# VPFE register map
Vendor: Texas Instruments
Peripheral module from a debugger description file (folder am437x).
Registers are 32-bit, access per field, no defined reset value unless marked. A register's access mark holds for its fields unless they carry their own. Offsets are as the file gives them; lines under a group give offsets from that group; [hi:lo] are bit positions; {n}, {i} and the like mark numbered series; 'fields as' and 'values as' point back to an identical list; <NAME> marks a mode.

## VPFE
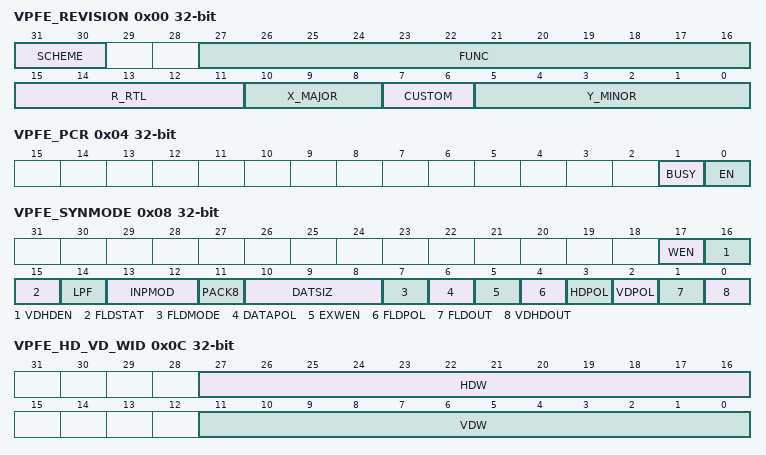
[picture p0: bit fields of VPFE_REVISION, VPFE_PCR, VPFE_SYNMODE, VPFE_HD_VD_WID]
0x00 VPFE_REVISION ro — IP Revision Identifier (X.Y.R) Used by software to track features, bugs, and compatibility
  [31:30] SCHEME — Used to distinguish between old scheme and current.
  [27:16] FUNC — Function value
  [15:11] R_RTL — RTL Version (R), maintained by IP design owner. [[br]]
  [10:8] X_MAJOR — Major Revision (X), maintained by IP specification owner. [[br]]
  [7:6] CUSTOM — Custom version
  [5:0] Y_MINOR — Minor Revision (Y), maintained by IP specification owner. [[br]]
0x04 VPFE_PCR — Peripheral Control Register
  [1] BUSY ro — VPFE busy bit
    1=en_2_0x1 (Busy); 0=en_1_0x0 (Not busy)
  [0] EN rw — This bit is latched by VD (start of frame)
    1=en_2_0x1 (Enable); 0=en_1_0x0 (Disable)
0x08 VPFE_SYNMODE — SYNC and Mode Set Register
  [17] WEN rw — Data write enable. [[br]]Controls whether or not input raw data is written to external memory. [[br]]This bit is latched by VD. [[br]]
    1=en_2_0x1 (Enable); 0=en_1_0x0 (Disable)
  [16] VDHDEN rw — VD/HD enable. [[br]]Activates internal timing generator to synchronize with external VD/HD signals. [[br]]This bit should be set to 1 when HD and VD signals are used at any time.
    1=en_2_0x1 (Enable); 0=en_1_0x0 (Disable)
  [15] FLDSTAT rw — Field status. [[br]]Indicates the status of the current field when in interlaced mode.
    1=en_2_0x1 (Even field); 0=en_1_0x0 (Odd field)
  [14] LPF rw — [[br]]3-tap low-pass (anti-aliasing) filter. [[br]]This bit is latched by VD.
    1=en_2_0x1 (On); 0=en_1_0x0 (Off)
  [13:12] INPMOD rw — Setting data input mode
    3=en_4_0x3 (Reserved); 2=en_3_0x2 (YCbCr 8-bit); 1=en_2_0x1 (YCbCr 16-bit); 0=en_1_0x0 (Raw data)
  [11] PACK8 rw — Pack to [[br]]8-bit/pixel (into external memory)
    1=en_2_0x1 (Pack to 8 bits/pixel); 0=en_1_0x0 (Normal (16 bits/pixel))
  [10:8] DATSIZ rw — CCD data width is only valid when INPMOD is set to 0.
    7=en_8_0x7 (8 bits); 6=en_7_0x6 (10 bits); 5=en_6_0x5 (11 bits); 4=en_5_0x4 (12 bits); 3=en_4_0x3 (13 bits); 2=en_3_0x2 (14 bits); 1=en_2_0x1 (15 bits); 0=en_1_0x0 (16 bits)
  [7] FLDMODE rw — Sensor field mode
    1=en_2_0x1 (Interlaced); 0=en_1_0x0 (Non-interlaced (progressive))
  [6] DATAPOL rw — Input data polarity
    1=en_2_0x1 (One's complement); 0=en_1_0x0 (Normal (no charge))
  [5] EXWEN rw — External WEN selection. [[br]]When set to 1 and when VDHDEN is set to 1, the WEN signal is used as the external memory write enable (to external memory). [[br]]The data is stored to memory only when the external sync (HD and VD) signals are active.
    1=en_2_0x1 (Use external WEN (write enable)); 0=en_1_0x0 (Do not use external WEN (write enable))
  [4] FLDPOL rw — Field indicator polarity
    1=en_2_0x1 (Negative); 0=en_1_0x0 (Positive)
  [3] HDPOL rw — HD sync polarity
    1=en_2_0x1 (Negative); 0=en_1_0x0 (Positive)
  [2] VDPOL rw — VD sync polarity
    1=en_2_0x1 (Negative); 0=en_1_0x0 (Positive)
  [1] FLDOUT rw — Field ID Direction
    1=en_2_0x1 (Output); 0=en_1_0x0 (Input)
  [0] VDHDOUT rw — VD/HD Sync Direction
    1=en_2_0x1 (Output); 0=en_1_0x0 (Input)
0x0C VPFE_HD_VD_WID
  [27:16] HDW rw — Width of HD sync pulse if output HDW+1 pixel clocks HDWIDTH is not used when HD is input, i.e when VDHDOUT in SYN_MODE register is cleared to '0' *This bit field is latched by VD
  [11:0] VDW rw — Width of VD sync pulse if output VDW+1 lines VDWIDTH is not used when VD is input, i.e when VDHDOUT in SYN_MODE register is cleared to '0' *This bit field is latched by VD
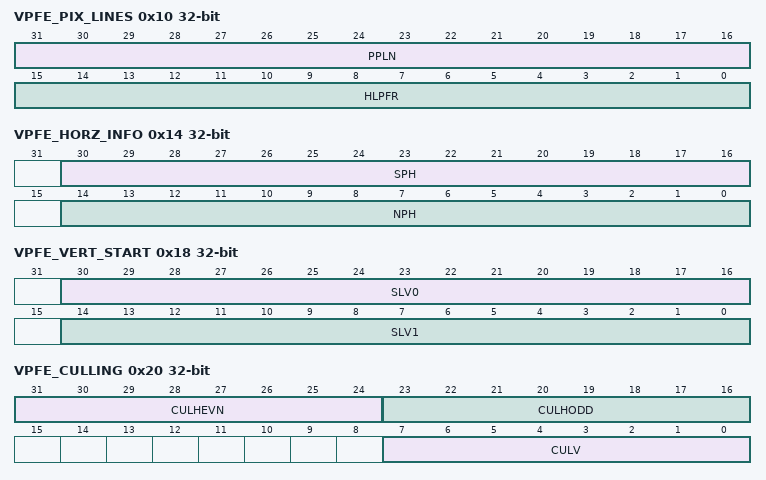
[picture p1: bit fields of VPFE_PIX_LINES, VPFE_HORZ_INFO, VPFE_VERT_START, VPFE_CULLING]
0x10 VPFE_PIX_LINES rw — Number of pixels in a horizontal line and number of lines in a frame
  [31:16] PPLN — Pixels per line - number of pixel clock periods in one line HD period = PPLN+1 pixel clocks PPLN is not used when HD and VD are inputs, i.e when VDHDOUT in SYN_MODE register is cleared to '0' *This bit field is latched by VD
  [15:0] HLPFR — Half lines per field or frame - sets number of half lines per frame or field VD period = (HLPFR+1)/2 lines HLPFR is not used when HD and VD are inputs, i.e when VDHDOUT in SYN_MODE register is cleared to '0' This tells the internal timing generator to generate the sufficient number of HD pulses in between two VD pulses. [[br]]If the sensor is an interlaced sensor, say for example, with a total of 525 (or 526) lines, then this field should be set to 525 (or 526). [[br]]This means that 525 (or 526) half lines are written for each field. [[br]]If the sensor is progressive, then this register should be set to be twice the number of lines to be written. [[br]]For example, if sensor outputs 1024 lines, this field should be set to 2048. [[br]]Therefore, for interlaced sensors, this field should be set to the total number of lines. [[br]]For progressive sensors, this field should be set to twice the total number of lines. [[br]]*This bit field is latched by VD
0x14 VPFE_HORZ_INFO — Horizontal Pixel Information Register
  [30:16] SPH rw — Start pixel, horizontal. [[br]]The SPH sets the pixel clock position at which data output to external memory begins, measured from the start of HD. [[br]]This bit field is latched by VD.
  [14:0] NPH rw — Number of pixels, horizontal. [[br]]NPH sets the number of horizontal pixels that is output to external memory = (NPH + 1) and 0xFFF0 (i.e., the number of horizontal output pixels truncates to multiples of 16). [[br]]This bit field is latched by VD.
0x18 VPFE_VERT_START — Vertical Line - Settings for the Starting Pixel Register
  [30:16] SLV0 rw — Start line, vertical (field 0). [[br]]SLV0 sets line at which data output to external memory will begin, measured from the start of VD. [[br]]This bit field is latched by VD.
  [14:0] SLV1 rw — Start line, vertical (field 1). [[br]]SLV1 sets line at which data output to external memory will begin, measured from the start of VD. [[br]]For a progressive sensor this field is ignored. [[br]]This bit field is latched by VD.
0x1C VPFE_VERT_LINES — Number of Vertical Lines Register
  [14:0] NLV rw — Number of lines, vertical. [[br]]NLV sets the number of vertical lines that will be output to external memory. [[br]]The number of lines output to external memory = (NLV + 1). [[br]]This bit field is latched by VD.
0x20 VPFE_CULLING — Culling Information in Horizontal and Vertical Directions Register
  [all] fields
    1=en_2_0x1 (Retain (to be saved to external memory)); 0=en_1_0x0 (CULLING (deletion))
  [31:24] CULHEVN rw — Horizontal Culling Pattern for Even Line, [[br]]8-bit mask. [[br]]LSB is first pixel, MSB is 8th pixel, then pattern repeats. [[br]]This bit field is latched by VD.
  [23:16] CULHODD rw — Horizontal Culling Pattern for Odd Line, [[br]]8-bit mask. [[br]]LSB is first pixel, MSB is 8th pixel, then pattern repeats. [[br]]This bit field is latched by VD.
  [7:0] CULV rw — Vertical Culling Pattern, [[br]]8-bit mask. [[br]]LSB is first line, MSB is 8th line, then pattern repeats. [[br]]This bit field is latched by VD.
0x24 VPFE_HSIZE_OFF — Horizontal Size Register
  [15:0] LNOFST rw — Address offset for each line. [[br]]LNOFST Sets offset for each output line in external memory Either 16 or 32 pixels depending on setting of PACK8. [[br]]The 5 LSB are ignored, and a zero is returned when read[[br]] the offset will be on a [[br]]32-byte boundary. [[br]]For optimal performance in the system, the address offset should be on a [[br]]256-byte boundary. [[br]]This bit field is latched by VD.
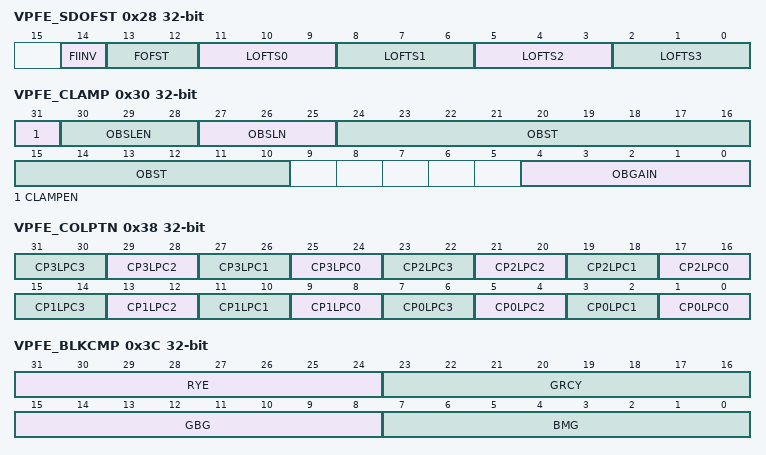
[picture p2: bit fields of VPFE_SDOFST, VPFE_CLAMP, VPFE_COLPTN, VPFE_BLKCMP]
0x28 VPFE_SDOFST — External Memory Line Offset Register
  [14] FIINV rw — Field identification signal inverse. [[br]]This field is latched by VD.
    1=en_2_0x1 (Inverse); 0=en_1_0x0 (Non inverse)
  [13:12] FOFST rw — Line offset value of field ID = 1. [[br]]This field is latched by VD.
    3=en_4_0x3 (+4 lines); 2=en_3_0x2 (+3 lines); 1=en_2_0x1 (+2 lines); 0=en_1_0x0 (+1 line)
  [11:9] LOFTS0 rw — Line offset values of even line and even field ID = 0. [[br]]This field is latched by VD.
    7=en_8_0x7 (-4 lines); 6=en_7_0x6 (-3 lines); 5=en_6_0x5 (-2 lines); 4=en_5_0x4 (-1 line); 3=en_4_0x3 (+4 lines); 2=en_3_0x2 (+3 lines); 1=en_2_0x1 (+2 lines); 0=en_1_0x0 (+1 line)
  [8:6] LOFTS1 rw — Line offset values of odd line and even field ID = 0. [[br]]This field is latched by VD.
    values as LOFTS0
  [5:3] LOFTS2 rw — Line offset values of even line and odd field ID = 1. [[br]]This field is latched by VD.
    values as LOFTS0
  [2:0] LOFTS3 rw — Line offset values of odd line and odd field ID = 1. [[br]]This field is latched by VD.
    values as LOFTS0
0x2C VPFE_SDR_ADDR rw — External Memory Address Register
  [31:0] ADR — 32-bit external memory starting address for VPFE output. [[br]]This bit field is latched by VD. [[br]]The address should be aligned on a 32-byte boundary. [[br]]Therefore, the 5 LSB's are ignored. [[br]]Furthermore, reading this register will always show the 5 LSB's as 0. [[br]]For optimal performance in the system, the address should be on a 256-byte boundary. [[br]]
0x30 VPFE_CLAMP — Optical Black Clamping Setting Register
  [31] CLAMPEN rw — Clamp enable. [[br]]Enable or disable clamping of CCD data based on the calculated average of optical black samples. [[br]]This bit is latched by VD.
    1=en_2_0x1 (Enable); 0=en_1_0x0 (Disable)
  [30:28] OBSLEN rw — Optical black sample length. [[br]]Number of Optical Black Sample pixels per line to include in the average calculation
    7=en_8_0x7 (Reserved); 6=en_7_0x6 (Reserved); 5=en_6_0x5 (Reserved); 4=en_5_0x4 (16 pixels); 3=en_4_0x3 (8 pixels); 2=en_3_0x2 (4 pixels); 1=en_2_0x1 (2 pixels); 0=en_1_0x0 (1 pixels)
  [27:25] OBSLN rw — Optical black sample lines. [[br]]Number of Optical Black Sample lines to include in the average calculation
    7=en_8_0x7 (Reserved); 6=en_7_0x6 (Reserved); 5=en_6_0x5 (Reserved); 4=en_5_0x4 (16 lines); 3=en_4_0x3 (8 lines); 2=en_3_0x2 (4 lines); 1=en_2_0x1 (2 lines); 0=en_1_0x0 (1 lines)
  [24:10] OBST rw — Start pixel of optical black samples. [[br]]The start pixel position of optical black samples, specified from the start of HD in pixel clocks.
  [4:0] OBGAIN rw — Gain to apply to the optical black average. [[br]]Multiply the optical black average with the specified gain. [[br]]1Fh = 1 + 15/16 1Eh = 1 + 14/16 ... [[br]]= ... [[br]]10h = 1 + 0/16 0Fh = 0 + 15/16 0Eh = 0 + 14/16 0Dh = 0 + 13/16 ... [[br]]= ... [[br]]02h = 0 + 2/16 01h = 0 + 1/16 00h = 0 + 0/16
0x34 VPFE_DCSUB — DC Clamp Register
  [13:0] DCSUB rw — DC level to subtract from CCD data. [[br]]The DC value set here is subtracted from the CCD data when OBS clamping is disabled - CLAMP.CLAMPEN.
0x38 VPFE_COLPTN rw — CCD Color Pattern Register
  [all] fields
    3=en_4_0x3 (B/Mg); 2=en_3_0x2 (Gb/G); 1=en_2_0x1 (Gr/Cy); 0=en_1_0x0 (R/Ye)
  [2n+25:2n+24] CP3LPC{n} (n=0..3) — Color Pattern for 3rd Line, Pixel counter = {n}
  [2n+17:2n+16] CP2LPC{n} (n=0..3) — Color Pattern for 2nd Line, Pixel counter = {n}
  [2n+9:2n+8] CP1LPC{n} (n=0..3) — Color Pattern for 1st Line, Pixel counter = {n}
  [2n+1:2n] CP0LPC{n} (n=0..3) — Color Pattern for 0th Line, Pixel counter = {n}
0x3C VPFE_BLKCMP rw — Black Compensation Register
  [31:24] RYE — Black level compensation for R/Ye pixels (-[[br]]128:+127). [[br]]2's complement, MSB is sign bit.
  [23:16] GRCY — Black level compensation for Gr/Cy pixels (-[[br]]128:+127). [[br]]2's complement, MSB is sign bit.
  [15:8] GBG — Black level compensation for Gb/G pixels (-[[br]]128:+127). [[br]]2's complement, MSB is sign bit.
  [7:0] BMG — Black level compensation for B/Mg pixels (-[[br]]128:+127). [[br]]2's complement, MSB is sign bit.
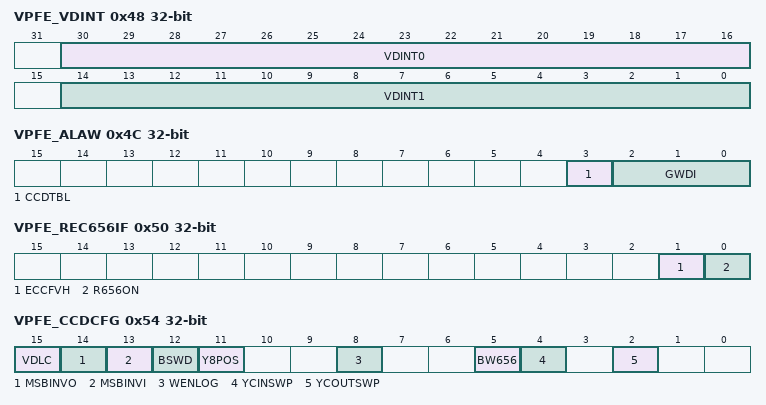
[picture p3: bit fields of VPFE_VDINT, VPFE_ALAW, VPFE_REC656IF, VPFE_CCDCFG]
0x48 VPFE_VDINT — VPFE Interrupt Control Register
  [30:16] VDINT0 rw — CCDC_VD0_INT interrupt timing. [[br]]Specify VDINT0 in units of horizontal lines from the start of VD pulse. [[br]]Resulting value is VDINT0+1. [[br]]Note that if the rising edge (or falling edge if programmed) of the HD lines up with the rising edge (or falling edge if programmed) of VD, the 1st HD is not counted. [[br]]
  [14:0] VDINT1 rw — CCDC_VD1_INT interrupt timing. [[br]]Specify VDINT1 in units of horizontal lines from the start of VD pulse. [[br]]Resulting value is VDINT1+1. [[br]]Note that if the rising edge (or falling edge if programmed) of the HD lines up with the rising edge (or falling edge if programmed) of VD, the 1st HD is not counted. [[br]]
0x4C VPFE_ALAW — ALAW Configuration Register
  [3] CCDTBL rw — Apply Gamma (A-LAW) to VPFE data saved to external memory
    1=en_2_0x1 (Enable); 0=en_1_0x0 (Disable)
  [2:0] GWDI rw — A-law Width Input (A-LAW table)
    6=en_7_0x6 (Bits 9-0); 5=en_6_0x5 (Bits 10-1); 4=en_5_0x4 (Bits 11-2); 3=en_4_0x3 (Bits 12-3); 2=en_3_0x2 (Bits 13-4); 1=en_2_0x1 (Bits 14-5); 0=en_1_0x0 (Bits 15-6)
0x50 VPFE_REC656IF — REC656IF Configuration Register
  [1] ECCFVH rw — FVH error correction enable
    1=en_2_0x1 (Enable); 0=en_1_0x0 (Disable)
  [0] R656ON rw — REC656 interface enable
    1=en_2_0x1 (Enable); 0=en_1_0x0 (Disable)
0x54 VPFE_CCDCFG — CCD Configuration Register
  [15] VDLC rw — Enable latching function registers on internal VSYNC. [[br]]If this bit is set, all the register fields that are VSYNC latched will take on new value immediately. [[br]]Care should be taken not to alter fields that can cause undesired behavior to the output data. [[br]]
    1=en_2_0x1 (Not latched on VSYNC); 0=en_1_0x0 (Latched on VSYNC)
  [14] MSBINVO rw — MSB of Chroma signal output inverted
    1=en_2_0x1 (MSB inverted); 0=en_1_0x0 (Normal)
  [13] MSBINVI rw — MSB of Chroma input signal stored to SDRAM inverted
    1=en_2_0x1 (MSB inverted); 0=en_1_0x0 (normal)
  [12] BSWD rw — Byte Swap Data stored to SDRAM
    1=en_2_0x1 (Swap Bytes); 0=en_1_0x0 (normal)
  [11] Y8POS rw — Location of Y signal when YCbCr 8bit data is input
    1=en_2_0x1 (odd pixel); 0=en_1_0x0 (even pixel)
  [8] WENLOG rw — Specifies CCD valid area
    1=en_2_0x1 (Internal valid signal and WEN signal is Ored logically); 0=en_1_0x0 (Internal valid signal and WEN signal is ANDed logically)
  [5] BW656 rw — The data width in CCIR656 input mode
    1=en_2_0x1 (10bits); 0=en_1_0x0 (8bits)
  [4] YCINSWP rw — Y input (YIN[[br]][7:0]) and C input (CIN[[br]][7:0]) are swapped
  [2] YCOUTSWP rw — Y output (YOUT[[br]][7:0]) and C output (COUT[[br]][7:0]) are swapped
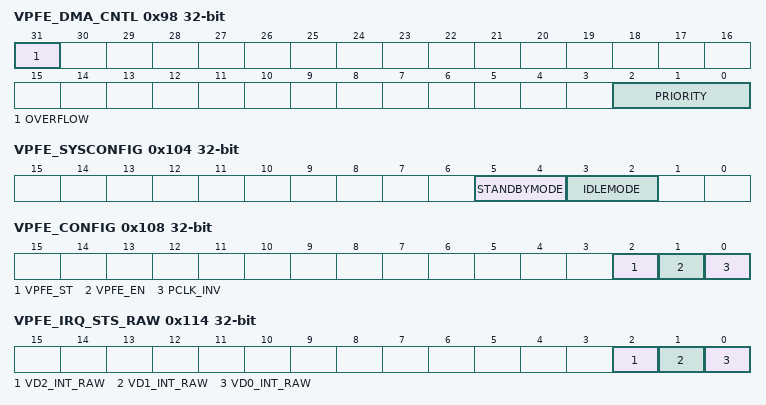
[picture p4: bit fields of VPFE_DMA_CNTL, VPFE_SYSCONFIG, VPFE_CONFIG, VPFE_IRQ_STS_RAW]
0x98 VPFE_DMA_CNTL — DMA Status and Control
  [31] OVERFLOW rw — DMA Overflow Flag Flag bit that is set when data is dropped due to a delay in writing data out the DMA interface. [[br]]This bit remains set until a 1 is written by software. [[br]]
    1=en_2_0x1 (Overflow has occurred); 0=en_1_0x0 (No overflow has occurred)
  [2:0] PRIORITY rw — Sets the priority that all command should be sent with on the DMA bus. [[br]]This register should only be modified when the Module is inactive or it could cause violations of the CBA specifications. [[br]]A value of 0 is the highest priority while a value of 0x7 would be the lowest priority
0x104 VPFE_SYSCONFIG — Clock management configuration
  [5:4] STANDBYMODE rw — Configuration of the local initiator state management mode. [[br]]By definition, initiator may generate read/write transaction as long as it is out of STANDBY state
    3=en_4_0x3 (Smart-Standby wakeup-capable mode: local initiator standby status depends on local conditions, i.e. the module's functional requirement from the initiator. IP module may generate (master-related) wakeup events when in standby state. Mode is only relevant if the appropriate IP module "mwakeup" output is implemented); 2=en_3_0x2 (Smart-standby mode: local initiator standby status depends on local conditions, i.e. the module's functional requirement from the initiator. IP module shall not generate (initiator-related) wakeup events); 1=en_2_0x1 (No-standby mode: local initiator is unconditionally placed out of standby state. Backup mode, for debug only.); 0=en_1_0x0 (Force-standby mode: local initiator is unconditionally placed in standby state. Backup mode, for debug only.)
  [3:2] IDLEMODE rw — Configuration of the local target state management mode. [[br]]By definition, target can handle read/write transaction as long as it is out of IDLE state
    3=en_4_0x3 (Smart-idle wakeup-capable mode: local target's idle state eventually follows (acknowledges) the system's idle requests, depending on the IP module's internal requirements. IP module may generate (IRQ- or DMA-request-related) wakeup events when in idle state. Mode is only relevant if the appropriate IP module "swakeup" output(s) is (are) implemented.); 2=en_3_0x2 (Smart-idle mode: local target's idle state eventually follows (acknowledges) the system's idle requests, depending on the IP module's internal requirements. IP module shall not generate (IRQ- or DMA-request-related) wakeup events.); 1=en_2_0x1 (No-idle mode: local target never enters idle state. Backup mode, for debug only.); 0=en_1_0x0 (Force-idle mode: local target's idle state follows (acknowledges) the system's idle requests unconditionally, i.e. regardless of the IP module's internal requirements. Backup mode, for debug only.)
0x108 VPFE_CONFIG — Module configuration register
  [2] VPFE_ST rw — VPFE Master OCP interface Status
    1=en_2_0x1 (OCP Master Interface is in Standby mode); 0=en_1_0x0 (OCP Master Interface is active)
  [1] VPFE_EN rw — VPFE Master OCP interface enable. [[br]]Software can has to use this bit to enable/disable the VPFE master OCP interface. [[br]]When the master OCP interface is disabled, it is placed in Standby mode. [[br]]Standby mode can also be entered by using the right setting on the STANDBYMODE field in the SYSCONFIG register
    1=en_2_0x1 (Enable VPFE Master OCP Interface); 0=en_1_0x0 (Disable VPFE Master OCP interface)
  [0] PCLK_INV rw — Pixel clock inversion enable
    1=en_2_0x1 (The pixel (CCDC) clock input to the VPFE is inverted before it is used internally in the module); 0=en_1_0x0 (Do not invert pixel (CCDC) clock)
0x114 VPFE_IRQ_STS_RAW — Interrupt raw status register
  [2] VD2_INT_RAW rw — CCDC VD2 interrupt status raw value - A read value of 1 from this register indicates that the VD2 interrupt status is 1. [[br]]- When the read value is 0 , software can write the value to 1 to set the interrupt - Writing a 0 to this bit has no effect. [[br]]
  [1] VD1_INT_RAW rw — CCDC VD1 interrupt status raw value - A read value of 1 from this register indicates that the VD1 interrupt status is 1. [[br]]- When the read value is 0 , software can write the value to 1 to set the interrupt - Writing a 0 to this bit has no effect
  [0] VD0_INT_RAW rw — CCDC VD0 interrupt status raw value - A read value of 1 from this register indicates that the VD0 interrupt status is 1. [[br]]- When the read value is 0 , software can write the value to 1 to set the interrupt - Writing a 0 to this bit has no effect. [[br]]
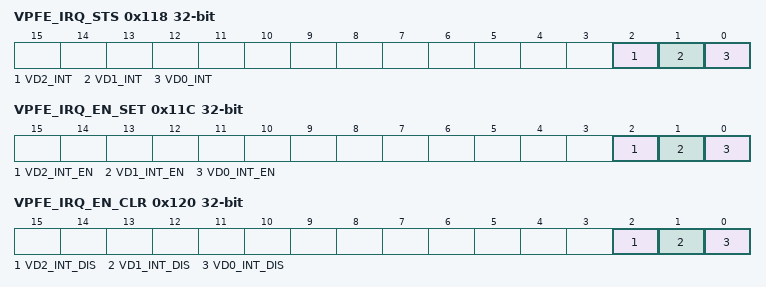
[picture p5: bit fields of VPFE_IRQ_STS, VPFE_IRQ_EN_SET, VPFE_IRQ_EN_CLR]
0x118 VPFE_IRQ_STS — Interrupt status register
  [2] VD2_INT rw — CCDC VD2 interrupt status value - A read value of 1 from this register indicates that the VD2 interrupt status is 1., if it is enabled - When the read value is 1 , software can write a 1 to clear the interrupt. [[br]]- Writing a 0 to this bit has no effect. [[br]]
  [1] VD1_INT rw — CCDC VD1 interrupt status value - A read value of 1 from this register indicates that the VD2 interrupt status is 1., if it is enabled - When the read value is 1 , software can write a 1 to clear the interrupt. [[br]]- Writing a 0 to this bit has no effect
  [0] VD0_INT rw — CCDC VD0 interrupt status value - A read value of 1 from this register indicates that the VD2 interrupt status is 1., if it is enabled - When the read value is 1 , software can write a 1 to clear the interrupt. [[br]]- Writing a 0 to this bit has no effect
0x11C VPFE_IRQ_EN_SET — Interrupt enable set
  [2] VD2_INT_EN rw — CCDC VD2 interrupt enable - Write 1 to enable this interrupt - Write 0 has no effect - Read 1 indicates interrupt is enabled - Read 0 indicates interrupt is not enabled. [[br]]
  [1] VD1_INT_EN rw — CCDC VD1 interrupt enable - Write 1 to enable this interrupt - Write 0 has no effect - Read 1 indicates interrupt is enabled - Read 0 indicates interrupt is not enabled
  [0] VD0_INT_EN rw — CCDC VD0 interrupt enable - Write 1 to enable this interrupt - Write 0 has no effect - Read 1 indicates interrupt is enabled - Read 0 indicates interrupt is not enabled
0x120 VPFE_IRQ_EN_CLR — Interrupt enable clear
  [2] VD2_INT_DIS rw — CCDC VD2 interrupt disable - Write 1 to disable this interrupt - Write 0 has no effect - Read 1 indicates interrupt is enabled - Read 0 indicates interrupt is not enabled
  [1] VD1_INT_DIS rw — CCDC VD1 interrupt disable - Write 1 to disable this interrupt - Write 0 has no effect - Read 1 indicates interrupt is enabled - Read 0 indicates interrupt is not enabled
  [0] VD0_INT_DIS rw — CCDC VD0 interrupt disable - Write 1 to disable this interrupt - Write 0 has no effect - Read 1 indicates interrupt is enabled - Read 0 indicates interrupt is not enabled
